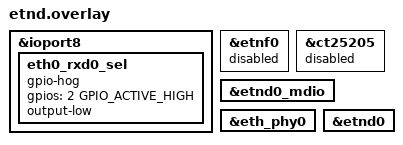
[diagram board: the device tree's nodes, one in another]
/*
 * Copyright (c) 2026 Renesas Electronics Corporation
 *
 * SPDX-License-Identifier: Apache-2.0
 */

/*
 * Ethernet TSN (ETND) with the on-board LAN8700 PHY at MDIO address 0x1f,
 * connected over MII, for all SoC variants of this board. Selects ETND
 * as the Ethernet interface instead of the default 10BASE-T1S (ETNF), which
 * is disabled so that ETND is the only network interface.
 *
 * Usage (board target y_ask_rh850u2c/<soc>):
 *   west build ... -- -DEXTRA_DTC_OVERLAY_FILE="etnd.overlay"
 *
 * It also drives P08_2 low so that P20_0 is routed to ETH0_RXD0 of the
 * 100BASE-TX interface instead of PMOD1.
 */

#include <dt-bindings/gpio/gpio.h>

&ioport8 {
	status = "okay";

	/* P08_2 low routes P20_0 to ETH0_RXD0 instead of SSIFACK */
	eth0_rxd0_sel {
		gpio-hog;
		gpios = <2 GPIO_ACTIVE_HIGH>;
		output-low;
	};
};

&etnf0 {
	status = "disabled";
};

&ct25205 {
	status = "disabled";
};

&etnd0_mdio {
	status = "okay";
};

&eth_phy0 {
	status = "okay";
};

&etnd0 {
	status = "okay";
};
